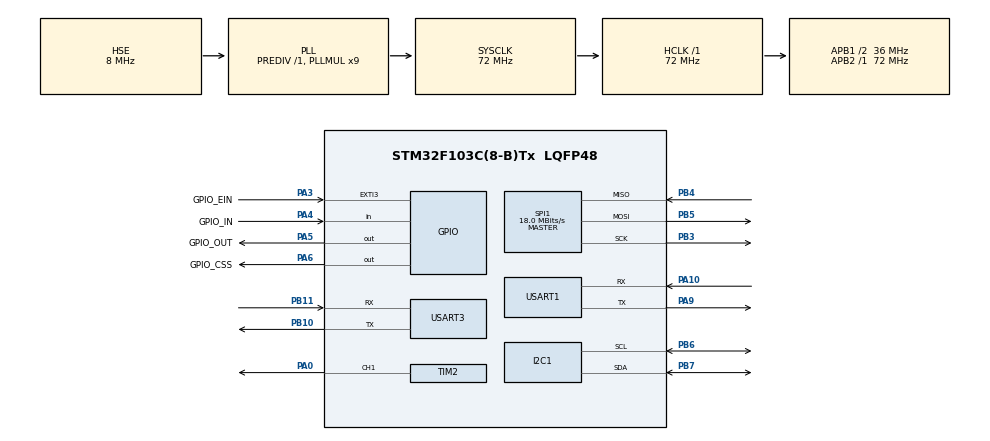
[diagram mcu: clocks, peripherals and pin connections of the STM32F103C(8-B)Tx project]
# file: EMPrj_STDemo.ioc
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Mcu.Family=STM32F1
Mcu.Name=STM32F103C(8-B)Tx
Mcu.Package=LQFP48
NVIC.EXTI3_IRQn=true\:0\:0\:false\:false\:true\:true\:true
NVIC.PriorityGroup=NVIC_PRIORITYGROUP_4
NVIC.TIM1_UP_IRQn=true\:0\:0\:false\:false\:true\:true\:true
NVIC.TIM2_IRQn=true\:0\:0\:false\:false\:true\:true\:true
NVIC.USART3_IRQn=true\:0\:0\:false\:false\:true\:true\:true
PA0-WKUP.Signal=S_TIM2_CH1_ETR
PA10.Mode=Asynchronous
PA10.Signal=USART1_RX
PA3.GPIO_Label=GPIO_EIN
PA3.GPIO_ModeDefaultEXTI=GPIO_MODE_IT_FALLING
PA3.GPIO_PuPd=GPIO_PULLUP
PA3.Signal=GPXTI3
PA4.GPIO_Label=GPIO_IN
PA4.GPIO_PuPd=GPIO_PULLUP
PA4.Signal=GPIO_Input
PA5.GPIO_Label=GPIO_OUT
PA5.GPIO_PuPd=GPIO_PULLUP
PA5.GPIO_Speed=GPIO_SPEED_FREQ_LOW
PA5.Signal=GPIO_Output
PA6.GPIO_Label=GPIO_CSS
PA6.GPIO_Speed=GPIO_SPEED_FREQ_HIGH
PA6.Signal=GPIO_Output
PA9.Mode=Asynchronous
PA9.Signal=USART1_TX
PB10.Mode=Asynchronous
PB10.Signal=USART3_TX
PB11.Mode=Asynchronous
PB11.Signal=USART3_RX
PB3.Mode=Full_Duplex_Master
PB3.Signal=SPI1_SCK
PB4.Mode=Full_Duplex_Master
PB4.Signal=SPI1_MISO
PB5.Mode=Full_Duplex_Master
PB5.Signal=SPI1_MOSI
PB6.Mode=I2C
PB6.Signal=I2C1_SCL
PB7.Mode=I2C
PB7.Signal=I2C1_SDA
PD0-OSC_IN.Mode=HSE-External-Oscillator
PD0-OSC_IN.Signal=RCC_OSC_IN
PD1-OSC_OUT.Mode=HSE-External-Oscillator
PD1-OSC_OUT.Signal=RCC_OSC_OUT
ProjectManager.HeapSize=0x200
ProjectManager.StackSize=0x400
ProjectManager.TargetToolchain=MDK-ARM V5.27
RCC.AHBFreq_Value=72000000
RCC.APB1CLKDivider=RCC_HCLK_DIV2
RCC.APB1Freq_Value=36000000
RCC.APB1TimFreq_Value=72000000
RCC.APB2Freq_Value=72000000
RCC.APB2TimFreq_Value=72000000
RCC.HCLKFreq_Value=72000000
RCC.PLLMUL=RCC_PLL_MUL9
RCC.PLLSourceVirtual=RCC_PLLSOURCE_HSE
RCC.SYSCLKFreq_VALUE=72000000
RCC.SYSCLKSource=RCC_SYSCLKSOURCE_PLLCLK
RCC.USBFreq_Value=72000000
SH.S_TIM2_CH1_ETR.0=TIM2_CH1,PWM Generation1 CH1
SPI1.BaudRatePrescaler=SPI_BAUDRATEPRESCALER_4
SPI1.CalculateBaudRate=18.0 MBits/s
SPI1.Direction=SPI_DIRECTION_2LINES
SPI1.Mode=SPI_MODE_MASTER
SPI1.VirtualType=VM_MASTER
TIM1.Period=1000
TIM1.Prescaler=72
TIM2.Channel-PWM\ Generation1\ CH1=TIM_CHANNEL_1
TIM2.Period=499
TIM2.Prescaler=71
USART1.VirtualMode=VM_ASYNC
USART3.VirtualMode=VM_ASYNC
VP_IWDG_VS_IWDG.Mode=IWDG_Activate
VP_SYS_VS_ND.Mode=No_Debug
VP_TIM1_VS_ClockSourceINT.Mode=Internal
VP_TIM2_VS_ClockSourceINT.Mode=Internal
board=custom

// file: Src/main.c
/* USER CODE BEGIN Header */
/**
  ******************************************************************************
  * @file           : main.c
  * @brief          : Main program body
  ******************************************************************************
  * @attention
  *
  * <h2><center>&copy; Copyright (c) 2020 STMicroelectronics.
  * All rights reserved.</center></h2>
  *
  * This software component is licensed by ST under BSD 3-Clause license,
  * the "License"; You may not use this file except in compliance with the
  * License. You may obtain a copy of the License at:
  *                        opensource.org/licenses/BSD-3-Clause
  *
  ******************************************************************************
  */
/* USER CODE END Header */

#include "main.h"
#include "i2c.h"
#include "iwdg.h"
#include "spi.h"
#include "tim.h"
#include "usart.h"
#include "gpio.h"

/* USER CODE BEGIN Includes */
#include <stdio.h>
/* USER CODE END Includes */

void SystemClock_Config(void);

int main(void)
{

  /* MCU Configuration--------------------------------------------------------*/

  /* Reset of all peripherals, Initializes the Flash interface and the Systick. */
  HAL_Init();

  /* Configure the system clock */
  SystemClock_Config();

  /* Initialize all configured peripherals */
  MX_GPIO_Init();
  MX_I2C1_Init();
  MX_TIM1_Init();
  MX_USART1_UART_Init();
  MX_IWDG_Init();
  MX_SPI1_Init();
  MX_TIM2_Init();
  MX_USART3_UART_Init();
  /* USER CODE BEGIN 2 */
	printf("system init\n");
	HAL_TIM_Base_Start_IT(&htim1);
	HAL_TIM_Base_Start_IT(&htim2);
	HAL_TIM_PWM_Start(&htim2,TIM_CHANNEL_1);
  /* USER CODE END 2 */

  /* Infinite loop */
  while (1)
  {

    /* USER CODE BEGIN 3 */
		HAL_IWDG_Refresh(&hiwdg);
  }
  /* USER CODE END 3 */
}

void SystemClock_Config(void)
{
  RCC_OscInitTypeDef RCC_OscInitStruct = {0};
  RCC_ClkInitTypeDef RCC_ClkInitStruct = {0};

  /** Initializes the CPU, AHB and APB busses clocks
  */
  RCC_OscInitStruct.OscillatorType = RCC_OSCILLATORTYPE_LSI|RCC_OSCILLATORTYPE_HSE;
  RCC_OscInitStruct.HSEState = RCC_HSE_ON;
  RCC_OscInitStruct.HSEPredivValue = RCC_HSE_PREDIV_DIV1;
  RCC_OscInitStruct.HSIState = RCC_HSI_ON;
  RCC_OscInitStruct.LSIState = RCC_LSI_ON;
  RCC_OscInitStruct.PLL.PLLState = RCC_PLL_ON;
  RCC_OscInitStruct.PLL.PLLSource = RCC_PLLSOURCE_HSE;
  RCC_OscInitStruct.PLL.PLLMUL = RCC_PLL_MUL9;
  if (HAL_RCC_OscConfig(&RCC_OscInitStruct) != HAL_OK)
  {
    Error_Handler();
  }
  /** Initializes the CPU, AHB and APB busses clocks
  */
  RCC_ClkInitStruct.ClockType = RCC_CLOCKTYPE_HCLK|RCC_CLOCKTYPE_SYSCLK
                              |RCC_CLOCKTYPE_PCLK1|RCC_CLOCKTYPE_PCLK2;
  RCC_ClkInitStruct.SYSCLKSource = RCC_SYSCLKSOURCE_PLLCLK;
  RCC_ClkInitStruct.AHBCLKDivider = RCC_SYSCLK_DIV1;
  RCC_ClkInitStruct.APB1CLKDivider = RCC_HCLK_DIV2;
  RCC_ClkInitStruct.APB2CLKDivider = RCC_HCLK_DIV1;

  if (HAL_RCC_ClockConfig(&RCC_ClkInitStruct, FLASH_LATENCY_2) != HAL_OK)
  {
    Error_Handler();
  }
}

/* USER CODE BEGIN 4 */
void HAL_TIM_PeriodElapsedCallback(TIM_HandleTypeDef *htim)
{
   if (htim->Instance == htim1.Instance)
   {
   }

}

void HAL_GPIO_EXTI_Callback(uint16_t GPIO_Pin)
{
	if(GPIO_Pin == GPIO_EIN_Pin)
	{

	}
}

void HAL_UART_RxCpltCallback(UART_HandleTypeDef *huart){
  if (huart->Instance == USART1){

	}
	 if (huart->Instance == USART3){

	}
}
/* USER CODE END 4 */

void Error_Handler(void)
{
}

/************************ (C) COPYRIGHT STMicroelectronics *****END OF FILE****/
